AUTOSAR XML (schema 314)
package /ComponentType
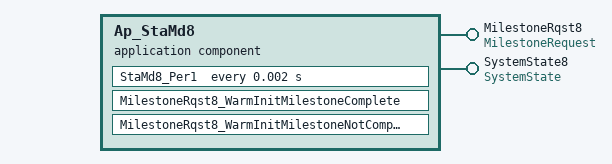
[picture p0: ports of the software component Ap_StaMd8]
  application software component type Ap_StaMd8
    provide port MilestoneRqst8: provided-interface=MilestoneRequest
      provided-com-specs:
        operation=WarmInitMilestoneComplete, queue-length=1
        operation=WarmInitMilestoneNotComplete, queue-length=1
    provide port SystemState8: mode-switch-com-spec{mode-group=Mode, queue-length=1}, provided-interface=SystemState
  internal behavior Ap_StaMd8_InternalBehavior: component=Ap_StaMd8
    operation invoked event OIT_MilestoneRqst8_WarmInitMilestoneComplete_MilestoneRqst8_WarmInitMilestoneComplete: start-on-event=MilestoneRqst8_WarmInitMilestoneComplete, operation=MilestoneRqst8.WarmInitMilestoneComplete
    operation invoked event OIT_MilestoneRqst8_WarmInitMilestoneNotComplete_MilestoneRqst8_WarmInitMilestoneNotComplete: start-on-event=MilestoneRqst8_WarmInitMilestoneNotComplete, operation=MilestoneRqst8.WarmInitMilestoneNotComplete
    timing event TMT_StaMd8_Per1: start-on-event=StaMd8_Per1, period=0.002
    exclusive area StaMds8_MilestoneRqst_WARMINIT_ExclArea
    port-api-options:
      enable-take-address=false, indirect-api=false, port=MilestoneRqst8
      enable-take-address=false, indirect-api=false, port=SystemState8
    runnable MilestoneRqst8_WarmInitMilestoneComplete: can-be-invoked-concurrently=true, can-enter-exclusive-area=StaMds8_MilestoneRqst_WARMINIT_ExclArea
    runnable MilestoneRqst8_WarmInitMilestoneNotComplete: can-be-invoked-concurrently=true, can-enter-exclusive-area=StaMds8_MilestoneRqst_WARMINIT_ExclArea
    runnable StaMd8_Per1
      mode switch point SWITCH_SystemState8_Mode: mode-group=SystemState8.Mode
  swc implementation Ap_StaMd8_Implementation: behavior=Ap_StaMd8_InternalBehavior
    code-descriptors:
      code Code: type=SRC
